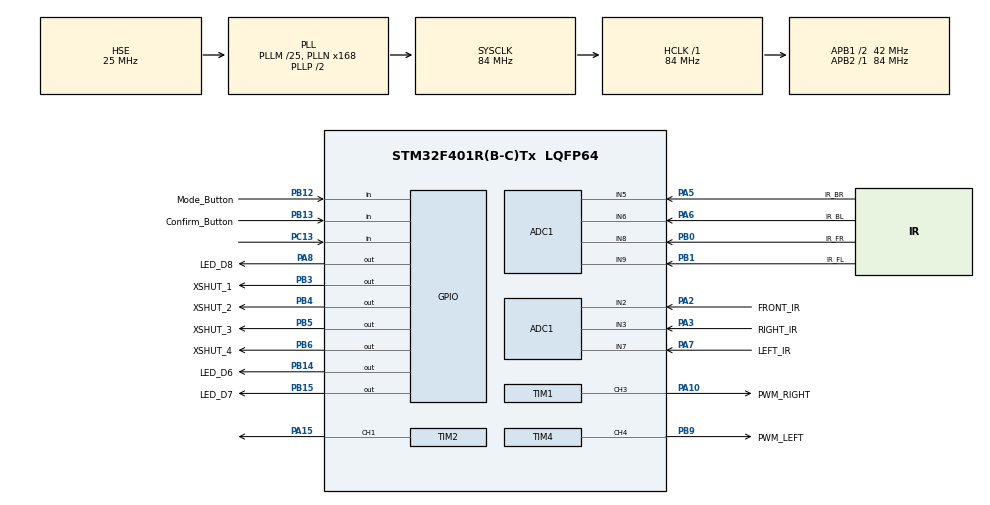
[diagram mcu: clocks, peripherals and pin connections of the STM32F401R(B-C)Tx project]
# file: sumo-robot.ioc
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ADC1.Channel-0\#ChannelRegularConversion=ADC_CHANNEL_3
ADC1.NbrOfConversionFlag=1
ADC1.Rank-0\#ChannelRegularConversion=1
ADC1.SamplingTime-0\#ChannelRegularConversion=ADC_SAMPLETIME_3CYCLES
ADC1.master=1
Mcu.Family=STM32F4
Mcu.Name=STM32F401R(B-C)Tx
Mcu.Package=LQFP64
NVIC.PriorityGroup=NVIC_PRIORITYGROUP_4
PA10.GPIO_Label=PWM_RIGHT
PA10.Signal=S_TIM1_CH3
PA15.Signal=S_TIM2_CH1_ETR
PA2.GPIO_Label=FRONT_IR
PA2.Signal=ADCx_IN2
PA3.GPIO_Label=RIGHT_IR
PA3.Signal=ADCx_IN3
PA5.GPIO_Label=IR_BR
PA5.Signal=ADCx_IN5
PA6.GPIO_Label=IR_BL
PA6.Signal=ADCx_IN6
PA7.GPIO_Label=LEFT_IR
PA7.Signal=ADCx_IN7
PA8.GPIO_Label=LED_D8
PA8.Signal=GPIO_Output
PB0.GPIO_Label=IR_FR
PB0.Signal=ADCx_IN8
PB1.GPIO_Label=IR_FL
PB1.Signal=ADCx_IN9
PB12.GPIO_Label=Mode_Button
PB12.GPIO_PuPd=GPIO_PULLUP
PB12.Signal=GPIO_Input
PB13.GPIO_Label=Confirm_Button
PB13.GPIO_PuPd=GPIO_PULLUP
PB13.Signal=GPIO_Input
PB14.GPIO_Label=LED_D6
PB14.Signal=GPIO_Output
PB15.GPIO_Label=LED_D7
PB15.Signal=GPIO_Output
PB3.GPIO_Label=XSHUT_1
PB3.Signal=GPIO_Output
PB4.GPIO_Label=XSHUT_2
PB4.Signal=GPIO_Output
PB5.GPIO_Label=XSHUT_3
PB5.Signal=GPIO_Output
PB6.GPIO_Label=XSHUT_4
PB6.Signal=GPIO_Output
PB9.GPIO_Label=PWM_LEFT
PB9.Signal=S_TIM4_CH4
PC13-ANTI_TAMP.Signal=GPIO_Input
PH0\ -\ OSC_IN.Mode=HSE-External-Oscillator
PH0\ -\ OSC_IN.Signal=RCC_OSC_IN
PH1\ -\ OSC_OUT.Mode=HSE-External-Oscillator
PH1\ -\ OSC_OUT.Signal=RCC_OSC_OUT
ProjectManager.HeapSize=0x200
ProjectManager.StackSize=0x400
ProjectManager.TargetToolchain=STM32CubeIDE
RCC.48MHZClocksFreq_Value=42000000
RCC.AHBFreq_Value=84000000
RCC.APB1CLKDivider=RCC_HCLK_DIV2
RCC.APB1Freq_Value=42000000
RCC.APB1TimFreq_Value=84000000
RCC.APB2Freq_Value=84000000
RCC.APB2TimFreq_Value=84000000
RCC.CortexFreq_Value=84000000
RCC.HCLKFreq_Value=84000000
RCC.HSE_VALUE=25000000
RCC.HSI_VALUE=16000000
RCC.LSE_VALUE=32768
RCC.PLLM=25
RCC.PLLN=168
RCC.PLLSourceVirtual=RCC_PLLSOURCE_HSE
RCC.SYSCLKFreq_VALUE=84000000
RCC.SYSCLKSource=RCC_SYSCLKSOURCE_PLLCLK
RCC.VCOOutputFreq_Value=168000000
SH.ADCx_IN2.0=ADC1_IN2,IN2
SH.ADCx_IN3.0=ADC1_IN3,IN3
SH.ADCx_IN5.0=ADC1_IN5,IN5
SH.ADCx_IN6.0=ADC1_IN6,IN6
SH.ADCx_IN7.0=ADC1_IN7,IN7
SH.ADCx_IN8.0=ADC1_IN8,IN8
SH.ADCx_IN9.0=ADC1_IN9,IN9
SH.S_TIM1_CH3.0=TIM1_CH3,PWM Generation3 CH3
SH.S_TIM2_CH1_ETR.0=TIM2_CH1,PWM Generation1 CH1
SH.S_TIM4_CH4.0=TIM4_CH4,PWM Generation4 CH4
TIM1.Channel-PWM\ Generation3\ CH3=TIM_CHANNEL_3
TIM1.Period=19999
TIM1.Prescaler=83
TIM2.Channel-PWM\ Generation1\ CH1=TIM_CHANNEL_1
TIM4.Channel-PWM\ Generation4\ CH4=TIM_CHANNEL_4
TIM4.Period=19999
TIM4.Prescaler=83
board=custom

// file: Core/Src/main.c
/* USER CODE BEGIN Header */
/**
  ******************************************************************************
  * @file           : main.c
  * @brief          : Main program body
  ******************************************************************************
  * @attention
  *
  * Copyright (c) 2026 STMicroelectronics.
  * All rights reserved.
  *
  * This software is licensed under terms that can be found in the LICENSE file
  * in the root directory of this software component.
  * If no LICENSE file comes with this software, it is provided AS-IS.
  *
  ******************************************************************************
  */
/* USER CODE END Header */
#include "main.h"

/* USER CODE BEGIN Includes */
#include "app_main.h"
#include "usart1_log.h"
/* USER CODE END Includes */

ADC_HandleTypeDef hadc1;

TIM_HandleTypeDef htim1;
TIM_HandleTypeDef htim2;
TIM_HandleTypeDef htim4;

void SystemClock_Config(void);
static void MX_GPIO_Init(void);
static void MX_ADC1_Init(void);
static void MX_TIM2_Init(void);
static void MX_TIM1_Init(void);
static void MX_TIM4_Init(void);

int main(void)
{

  /* MCU Configuration--------------------------------------------------------*/

  /* Reset of all peripherals, Initializes the Flash interface and the Systick. */
  HAL_Init();

  /* Configure the system clock */
  SystemClock_Config();

  /* Initialize all configured peripherals */
  MX_GPIO_Init();
  MX_ADC1_Init();
  MX_TIM2_Init();
  MX_TIM1_Init();
  MX_TIM4_Init();
  /* USER CODE BEGIN 2 */

    app_main();
  /* USER CODE END 2 */

  /* Infinite loop */
  while (1)
  {

  }
}

void SystemClock_Config(void)
{
  RCC_OscInitTypeDef RCC_OscInitStruct = {0};
  RCC_ClkInitTypeDef RCC_ClkInitStruct = {0};

  /** Configure the main internal regulator output voltage
  */
  __HAL_RCC_PWR_CLK_ENABLE();
  __HAL_PWR_VOLTAGESCALING_CONFIG(PWR_REGULATOR_VOLTAGE_SCALE2);

  /** Initializes the RCC Oscillators according to the specified parameters
  * in the RCC_OscInitTypeDef structure.
  */
  RCC_OscInitStruct.OscillatorType = RCC_OSCILLATORTYPE_HSE;
  RCC_OscInitStruct.HSEState = RCC_HSE_ON;
  RCC_OscInitStruct.PLL.PLLState = RCC_PLL_ON;
  RCC_OscInitStruct.PLL.PLLSource = RCC_PLLSOURCE_HSE;
  RCC_OscInitStruct.PLL.PLLM = 25;
  RCC_OscInitStruct.PLL.PLLN = 168;
  RCC_OscInitStruct.PLL.PLLP = RCC_PLLP_DIV2;
  RCC_OscInitStruct.PLL.PLLQ = 4;
  if (HAL_RCC_OscConfig(&RCC_OscInitStruct) != HAL_OK)
  {
    Error_Handler();
  }

  /** Initializes the CPU, AHB and APB buses clocks
  */
  RCC_ClkInitStruct.ClockType = RCC_CLOCKTYPE_HCLK|RCC_CLOCKTYPE_SYSCLK
                              |RCC_CLOCKTYPE_PCLK1|RCC_CLOCKTYPE_PCLK2;
  RCC_ClkInitStruct.SYSCLKSource = RCC_SYSCLKSOURCE_PLLCLK;
  RCC_ClkInitStruct.AHBCLKDivider = RCC_SYSCLK_DIV1;
  RCC_ClkInitStruct.APB1CLKDivider = RCC_HCLK_DIV2;
  RCC_ClkInitStruct.APB2CLKDivider = RCC_HCLK_DIV1;

  if (HAL_RCC_ClockConfig(&RCC_ClkInitStruct, FLASH_LATENCY_2) != HAL_OK)
  {
    Error_Handler();
  }
}

static void MX_ADC1_Init(void)
{

  ADC_ChannelConfTypeDef sConfig = {0};

  /** Configure the global features of the ADC (Clock, Resolution, Data Alignment and number of conversion)
  */
  hadc1.Instance = ADC1;
  hadc1.Init.ClockPrescaler = ADC_CLOCK_SYNC_PCLK_DIV4;
  hadc1.Init.Resolution = ADC_RESOLUTION_12B;
  hadc1.Init.ScanConvMode = DISABLE;
  hadc1.Init.ContinuousConvMode = DISABLE;
  hadc1.Init.DiscontinuousConvMode = DISABLE;
  hadc1.Init.ExternalTrigConvEdge = ADC_EXTERNALTRIGCONVEDGE_NONE;
  hadc1.Init.ExternalTrigConv = ADC_SOFTWARE_START;
  hadc1.Init.DataAlign = ADC_DATAALIGN_RIGHT;
  hadc1.Init.NbrOfConversion = 1;
  hadc1.Init.DMAContinuousRequests = DISABLE;
  hadc1.Init.EOCSelection = ADC_EOC_SINGLE_CONV;
  if (HAL_ADC_Init(&hadc1) != HAL_OK)
  {
    Error_Handler();
  }

  /** Configure for the selected ADC regular channel its corresponding rank in the sequencer and its sample time.
  */
  sConfig.Channel = ADC_CHANNEL_3;
  sConfig.Rank = 1;
  sConfig.SamplingTime = ADC_SAMPLETIME_3CYCLES;
  if (HAL_ADC_ConfigChannel(&hadc1, &sConfig) != HAL_OK)
  {
    Error_Handler();
  }

}

static void MX_TIM1_Init(void)
{

  TIM_MasterConfigTypeDef sMasterConfig = {0};
  TIM_OC_InitTypeDef sConfigOC = {0};
  TIM_BreakDeadTimeConfigTypeDef sBreakDeadTimeConfig = {0};

  htim1.Instance = TIM1;
  htim1.Init.Prescaler = 83;
  htim1.Init.CounterMode = TIM_COUNTERMODE_UP;
  htim1.Init.Period = 19999;
  htim1.Init.ClockDivision = TIM_CLOCKDIVISION_DIV1;
  htim1.Init.RepetitionCounter = 0;
  htim1.Init.AutoReloadPreload = TIM_AUTORELOAD_PRELOAD_DISABLE;
  if (HAL_TIM_PWM_Init(&htim1) != HAL_OK)
  {
    Error_Handler();
  }
  sMasterConfig.MasterOutputTrigger = TIM_TRGO_RESET;
  sMasterConfig.MasterSlaveMode = TIM_MASTERSLAVEMODE_DISABLE;
  if (HAL_TIMEx_MasterConfigSynchronization(&htim1, &sMasterConfig) != HAL_OK)
  {
    Error_Handler();
  }
  sConfigOC.OCMode = TIM_OCMODE_PWM1;
  sConfigOC.Pulse = 0;
  sConfigOC.OCPolarity = TIM_OCPOLARITY_HIGH;
  sConfigOC.OCNPolarity = TIM_OCNPOLARITY_HIGH;
  sConfigOC.OCFastMode = TIM_OCFAST_DISABLE;
  sConfigOC.OCIdleState = TIM_OCIDLESTATE_RESET;
  sConfigOC.OCNIdleState = TIM_OCNIDLESTATE_RESET;
  if (HAL_TIM_PWM_ConfigChannel(&htim1, &sConfigOC, TIM_CHANNEL_3) != HAL_OK)
  {
    Error_Handler();
  }
  sBreakDeadTimeConfig.OffStateRunMode = TIM_OSSR_DISABLE;
  sBreakDeadTimeConfig.OffStateIDLEMode = TIM_OSSI_DISABLE;
  sBreakDeadTimeConfig.LockLevel = TIM_LOCKLEVEL_OFF;
  sBreakDeadTimeConfig.DeadTime = 0;
  sBreakDeadTimeConfig.BreakState = TIM_BREAK_DISABLE;
  sBreakDeadTimeConfig.BreakPolarity = TIM_BREAKPOLARITY_HIGH;
  sBreakDeadTimeConfig.AutomaticOutput = TIM_AUTOMATICOUTPUT_DISABLE;
  if (HAL_TIMEx_ConfigBreakDeadTime(&htim1, &sBreakDeadTimeConfig) != HAL_OK)
  {
    Error_Handler();
  }
  HAL_TIM_MspPostInit(&htim1);

}

static void MX_TIM2_Init(void)
{

  TIM_MasterConfigTypeDef sMasterConfig = {0};
  TIM_OC_InitTypeDef sConfigOC = {0};

  htim2.Instance = TIM2;
  htim2.Init.Prescaler = 0;
  htim2.Init.CounterMode = TIM_COUNTERMODE_UP;
  htim2.Init.Period = 4294967295;
  htim2.Init.ClockDivision = TIM_CLOCKDIVISION_DIV1;
  htim2.Init.AutoReloadPreload = TIM_AUTORELOAD_PRELOAD_DISABLE;
  if (HAL_TIM_PWM_Init(&htim2) != HAL_OK)
  {
    Error_Handler();
  }
  sMasterConfig.MasterOutputTrigger = TIM_TRGO_RESET;
  sMasterConfig.MasterSlaveMode = TIM_MASTERSLAVEMODE_DISABLE;
  if (HAL_TIMEx_MasterConfigSynchronization(&htim2, &sMasterConfig) != HAL_OK)
  {
    Error_Handler();
  }
  sConfigOC.OCMode = TIM_OCMODE_PWM1;
  sConfigOC.Pulse = 0;
  sConfigOC.OCPolarity = TIM_OCPOLARITY_HIGH;
  sConfigOC.OCFastMode = TIM_OCFAST_DISABLE;
  if (HAL_TIM_PWM_ConfigChannel(&htim2, &sConfigOC, TIM_CHANNEL_1) != HAL_OK)
  {
    Error_Handler();
  }
  HAL_TIM_MspPostInit(&htim2);

}

static void MX_TIM4_Init(void)
{

  TIM_MasterConfigTypeDef sMasterConfig = {0};
  TIM_OC_InitTypeDef sConfigOC = {0};

  htim4.Instance = TIM4;
  htim4.Init.Prescaler = 83;
  htim4.Init.CounterMode = TIM_COUNTERMODE_UP;
  htim4.Init.Period = 19999;
  htim4.Init.ClockDivision = TIM_CLOCKDIVISION_DIV1;
  htim4.Init.AutoReloadPreload = TIM_AUTORELOAD_PRELOAD_DISABLE;
  if (HAL_TIM_PWM_Init(&htim4) != HAL_OK)
  {
    Error_Handler();
  }
  sMasterConfig.MasterOutputTrigger = TIM_TRGO_RESET;
  sMasterConfig.MasterSlaveMode = TIM_MASTERSLAVEMODE_DISABLE;
  if (HAL_TIMEx_MasterConfigSynchronization(&htim4, &sMasterConfig) != HAL_OK)
  {
    Error_Handler();
  }
  sConfigOC.OCMode = TIM_OCMODE_PWM1;
  sConfigOC.Pulse = 0;
  sConfigOC.OCPolarity = TIM_OCPOLARITY_HIGH;
  sConfigOC.OCFastMode = TIM_OCFAST_DISABLE;
  if (HAL_TIM_PWM_ConfigChannel(&htim4, &sConfigOC, TIM_CHANNEL_4) != HAL_OK)
  {
    Error_Handler();
  }
  HAL_TIM_MspPostInit(&htim4);

}

static void MX_GPIO_Init(void)
{
  GPIO_InitTypeDef GPIO_InitStruct = {0};

  /* GPIO Ports Clock Enable */
  __HAL_RCC_GPIOC_CLK_ENABLE();
  __HAL_RCC_GPIOH_CLK_ENABLE();
  __HAL_RCC_GPIOA_CLK_ENABLE();
  __HAL_RCC_GPIOB_CLK_ENABLE();

  /*Configure GPIO pin Output Level */
  HAL_GPIO_WritePin(GPIOB, LED_D6_Pin|LED_D7_Pin|XSHUT_1_Pin|XSHUT_2_Pin
                          |XSHUT_3_Pin|XSHUT_4_Pin, GPIO_PIN_RESET);

  /*Configure GPIO pin Output Level */
  HAL_GPIO_WritePin(LED_D8_GPIO_Port, LED_D8_Pin, GPIO_PIN_RESET);

  /*Configure GPIO pin : PC13 */
  GPIO_InitStruct.Pin = GPIO_PIN_13;
  GPIO_InitStruct.Mode = GPIO_MODE_INPUT;
  GPIO_InitStruct.Pull = GPIO_NOPULL;
  HAL_GPIO_Init(GPIOC, &GPIO_InitStruct);

  /*Configure GPIO pins : Mode_Button_Pin Confirm_Button_Pin */
  GPIO_InitStruct.Pin = Mode_Button_Pin|Confirm_Button_Pin;
  GPIO_InitStruct.Mode = GPIO_MODE_INPUT;
  GPIO_InitStruct.Pull = GPIO_PULLUP;
  HAL_GPIO_Init(GPIOB, &GPIO_InitStruct);

  /*Configure GPIO pins : LED_D6_Pin LED_D7_Pin XSHUT_1_Pin XSHUT_2_Pin
                           XSHUT_3_Pin XSHUT_4_Pin */
  GPIO_InitStruct.Pin = LED_D6_Pin|LED_D7_Pin|XSHUT_1_Pin|XSHUT_2_Pin
                          |XSHUT_3_Pin|XSHUT_4_Pin;
  GPIO_InitStruct.Mode = GPIO_MODE_OUTPUT_PP;
  GPIO_InitStruct.Pull = GPIO_NOPULL;
  GPIO_InitStruct.Speed = GPIO_SPEED_FREQ_LOW;
  HAL_GPIO_Init(GPIOB, &GPIO_InitStruct);

  /*Configure GPIO pin : LED_D8_Pin */
  GPIO_InitStruct.Pin = LED_D8_Pin;
  GPIO_InitStruct.Mode = GPIO_MODE_OUTPUT_PP;
  GPIO_InitStruct.Pull = GPIO_NOPULL;
  GPIO_InitStruct.Speed = GPIO_SPEED_FREQ_LOW;
  HAL_GPIO_Init(LED_D8_GPIO_Port, &GPIO_InitStruct);

  /* USER CODE BEGIN MX_GPIO_Init_2 */
  HAL_NVIC_SetPriority(EXTI15_10_IRQn, 0, 0);
  HAL_NVIC_EnableIRQ(EXTI15_10_IRQn);

  /* USER CODE END MX_GPIO_Init_2 */
}

void Error_Handler(void)
{
  __disable_irq();
  while (1)
  {
  }
}
